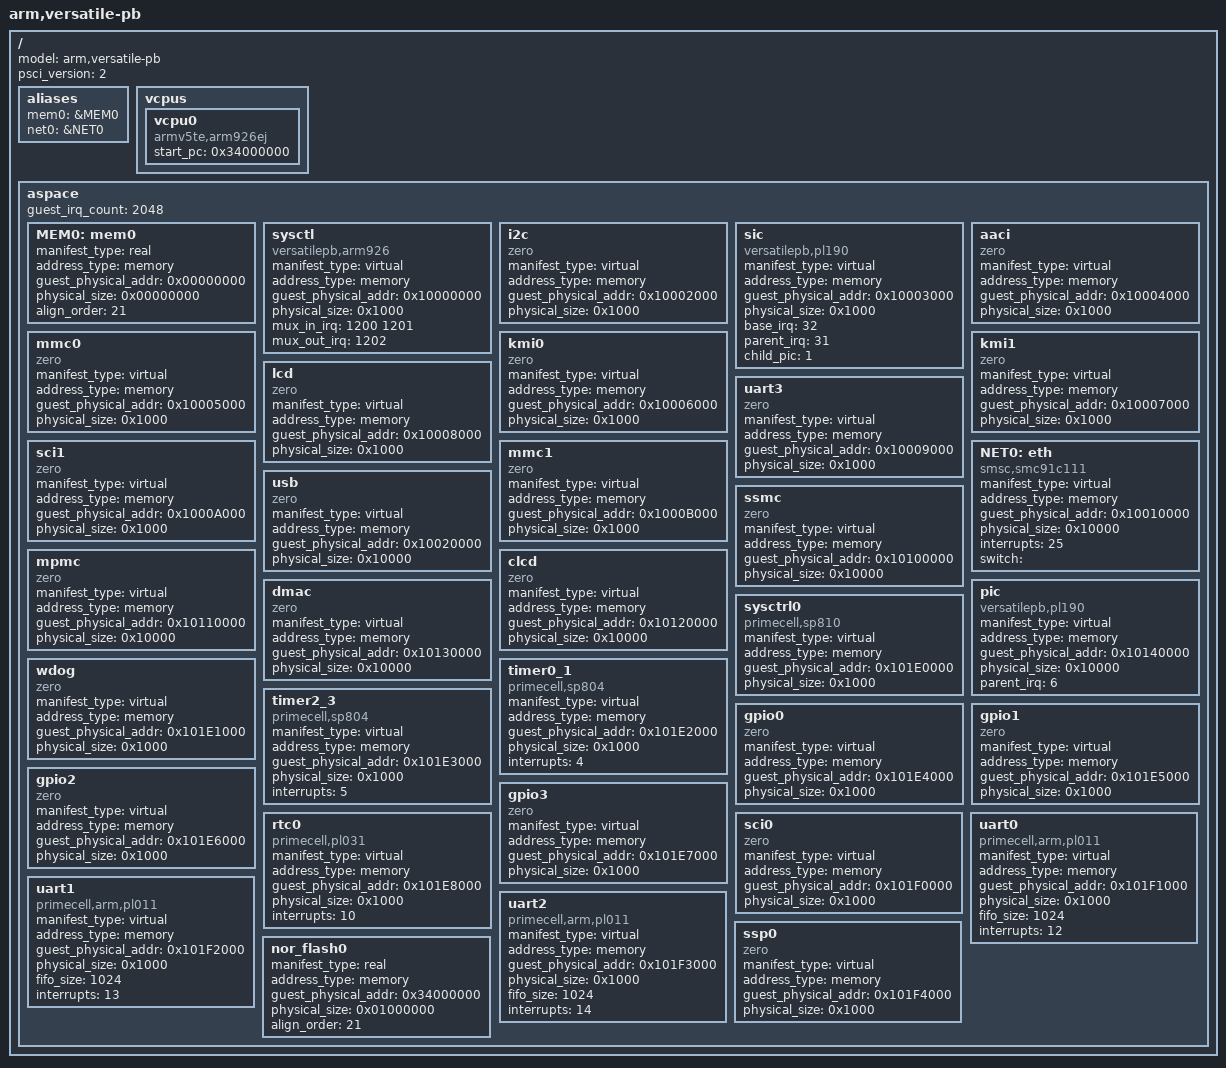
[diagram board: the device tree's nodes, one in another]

/dts-v1/;

/ {
	model = "arm,versatile-pb";
	device_type = "guest";
	psci_version = <2>;

	aliases {
		mem0 = &MEM0;
		net0 = &NET0;
	};

	vcpus {
		vcpu0 {
			device_type = "vcpu";
			compatible = "armv5te,arm926ej";
			start_pc = <0x34000000>;
		};
	};
	
	aspace {
		guest_irq_count = <2048>;

		MEM0: mem0 {
			manifest_type = "real";
			address_type = "memory";
			guest_physical_addr = <0x00000000>;
			physical_size = <0x00000000>; /* Override this before guest creation */
			align_order = <21>; /* Align alloced memory to 2MB */
			device_type = "alloced_ram";
		};

		sysctl {
			manifest_type = "virtual";
			address_type = "memory";
			guest_physical_addr = <0x10000000>;
			physical_size = <0x1000>;
			device_type = "sys";
			compatible = "versatilepb,arm926";
			mux_in_irq = <1200 1201>;
			mux_out_irq = <1202>;
		};

		i2c { /* No I2C */
			manifest_type = "virtual";
			address_type = "memory";
			guest_physical_addr = <0x10002000>;
			physical_size = <0x1000>;
			device_type = "misc";
			compatible = "zero";
		};

		sic {
			manifest_type = "virtual";
			address_type = "memory";
			guest_physical_addr = <0x10003000>;
			physical_size = <0x1000>;
			device_type = "pic";
			compatible = "versatilepb,pl190";
			base_irq = <32>;
			parent_irq = <31>;
			child_pic = <1>;
		};

		aaci { /* No Audio Controller */
			manifest_type = "virtual";
			address_type = "memory";
			guest_physical_addr = <0x10004000>;
			physical_size = <0x1000>;
			device_type = "misc";
			compatible = "zero";
		};

		mmc0 { /* No Multimedia Card 0 Interface */
			manifest_type = "virtual";
			address_type = "memory";
			guest_physical_addr = <0x10005000>;
			physical_size = <0x1000>;
			device_type = "misc";
			compatible = "zero";
		};

		kmi0 { /* No Keyboard/Mouse Interface */
			manifest_type = "virtual";
			address_type = "memory";
			guest_physical_addr = <0x10006000>;
			physical_size = <0x1000>;
			device_type = "misc";
			compatible = "zero";
		};

		kmi1 { /* No Keyboard/Mouse Interface */
			manifest_type = "virtual";
			address_type = "memory";
			guest_physical_addr = <0x10007000>;
			physical_size = <0x1000>;
			device_type = "misc";
			compatible = "zero";
		};

		lcd { /* No character LCD Interface */
			manifest_type = "virtual";
			address_type = "memory";
			guest_physical_addr = <0x10008000>;
			physical_size = <0x1000>;
			device_type = "misc";
			compatible = "zero";
		};

		uart3 { /* No uart3 Interface */
			manifest_type = "virtual";
			address_type = "memory";
			guest_physical_addr = <0x10009000>;
			physical_size = <0x1000>;
			device_type = "misc";
			compatible = "zero";
		};

		sci1 { /* No MMC 1 Interface */
			manifest_type = "virtual";
			address_type = "memory";
			guest_physical_addr = <0x1000A000>;
			physical_size = <0x1000>;
			device_type = "misc";
			compatible = "zero";
		};

		mmc1 { /* No MMC 1 Interface */
			manifest_type = "virtual";
			address_type = "memory";
			guest_physical_addr = <0x1000B000>;
			physical_size = <0x1000>;
			device_type = "misc";
			compatible = "zero";
		};

		NET0: eth {
			manifest_type = "virtual";
			address_type = "memory";
			guest_physical_addr = <0x10010000>;
			physical_size = <0x10000>;
			device_type = "nic";
			compatible = "smsc,smc91c111";
			interrupts = <25>;
			switch = ""; /* Override this before guest creation */
		};

		usb { /* No USB Interface */
			manifest_type = "virtual";
			address_type = "memory";
			guest_physical_addr = <0x10020000>;
			physical_size = <0x10000>;
			device_type = "misc";
			compatible = "zero";
		};

		ssmc { /* No SSMC Interface */
			manifest_type = "virtual";
			address_type = "memory";
			guest_physical_addr = <0x10100000>;
			physical_size = <0x10000>;
			device_type = "misc";
			compatible = "zero";
		};

		mpmc { /* No MPMC Interface */
			manifest_type = "virtual";
			address_type = "memory";
			guest_physical_addr = <0x10110000>;
			physical_size = <0x10000>;
			device_type = "misc";
			compatible = "zero";
		};

		clcd { /* No colour LCD Interface */
			manifest_type = "virtual";
			address_type = "memory";
			guest_physical_addr = <0x10120000>;
			physical_size = <0x10000>;
			device_type = "misc";
			compatible = "zero";
		};

		dmac { /* No DMAC Interface */
			manifest_type = "virtual";
			address_type = "memory";
			guest_physical_addr = <0x10130000>;
			physical_size = <0x10000>;
			device_type = "misc";
			compatible = "zero";
		};

		pic {
			manifest_type = "virtual";
			address_type = "memory";
			guest_physical_addr = <0x10140000>;
			physical_size = <0x10000>;
			device_type = "pic";
			compatible = "versatilepb,pl190";
			parent_irq = <6>;
		};

		sysctrl0 {
			manifest_type = "virtual";
			address_type = "memory";
			guest_physical_addr = <0x101E0000>;
			physical_size = <0x1000>;
			device_type = "sys";
			compatible = "primecell,sp810";
		};

		wdog { /* No Watchdog Interface */
			manifest_type = "virtual";
			address_type = "memory";
			guest_physical_addr = <0x101E1000>;
			physical_size = <0x1000>;
			device_type = "misc";
			compatible = "zero";
		};

		timer0_1 {
			manifest_type = "virtual";
			address_type = "memory";
			guest_physical_addr = <0x101E2000>;
			physical_size = <0x1000>;
			device_type = "timer";
			compatible = "primecell,sp804";
			interrupts = <4>;
		};

		timer2_3 {
			manifest_type = "virtual";
			address_type = "memory";
			guest_physical_addr = <0x101E3000>;
			physical_size = <0x1000>;
			device_type = "timer";
			compatible = "primecell,sp804";
			interrupts = <5>;
		};

		gpio0 { /* No GPIO 0 Interface */
			manifest_type = "virtual";
			address_type = "memory";
			guest_physical_addr = <0x101E4000>;
			physical_size = <0x1000>;
			device_type = "misc";
			compatible = "zero";
		};

		gpio1 { /* No GPIO 1 Interface */
			manifest_type = "virtual";
			address_type = "memory";
			guest_physical_addr = <0x101E5000>;
			physical_size = <0x1000>;
			device_type = "misc";
			compatible = "zero";
		};

		gpio2 { /* No GPIO 2 Interface */
			manifest_type = "virtual";
			address_type = "memory";
			guest_physical_addr = <0x101E6000>;
			physical_size = <0x1000>;
			device_type = "misc";
			compatible = "zero";
		};

		gpio3 { /* No GPIO 3 Interface */
			manifest_type = "virtual";
			address_type = "memory";
			guest_physical_addr = <0x101E7000>;
			physical_size = <0x1000>;
			device_type = "misc";
			compatible = "zero";
		};

		rtc0 {
			manifest_type = "virtual";
			address_type = "memory";
			guest_physical_addr = <0x101E8000>;
			physical_size = <0x1000>;
			device_type = "rtc";
			compatible = "primecell,pl031";
			interrupts = <10>;
		};

		sci0 { /* No Smart Card 0 Interface */
			manifest_type = "virtual";
			address_type = "memory";
			guest_physical_addr = <0x101F0000>;
			physical_size = <0x1000>;
			device_type = "misc";
			compatible = "zero";
		};

		uart0 {
			manifest_type = "virtual";
			address_type = "memory";
			guest_physical_addr = <0x101F1000>;
			physical_size = <0x1000>;
			device_type = "serial";
			compatible = "primecell,arm,pl011";
			fifo_size = <1024>;
			interrupts = <12>;
		};

		uart1 {
			manifest_type = "virtual";
			address_type = "memory";
			guest_physical_addr = <0x101F2000>;
			physical_size = <0x1000>;
			device_type = "serial";
			compatible = "primecell,arm,pl011";
			fifo_size = <1024>;
			interrupts = <13>;
		};

		uart2 {
			manifest_type = "virtual";
			address_type = "memory";
			guest_physical_addr = <0x101F3000>;
			physical_size = <0x1000>;
			device_type = "serial";
			compatible = "primecell,arm,pl011";
			fifo_size = <1024>;
			interrupts = <14>;
		};

		ssp0 { /* No Synchronous Serial Port Interface */
			manifest_type = "virtual";
			address_type = "memory";
			guest_physical_addr = <0x101F4000>;
			physical_size = <0x1000>;
			device_type = "misc";
			compatible = "zero";
		};

		nor_flash0 {
			manifest_type = "real";
			address_type = "memory";
			guest_physical_addr = <0x34000000>;
			physical_size = <0x01000000>;
			align_order = <21>; /* Align alloced memory to 2MB */
			device_type = "alloced_rom";
		};
	};
};
